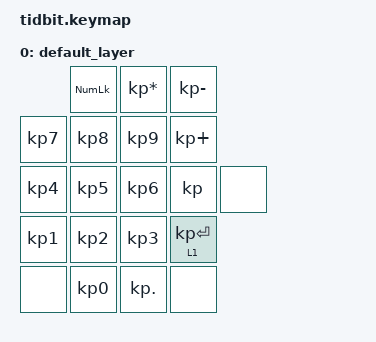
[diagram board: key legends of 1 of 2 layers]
/*
 * Copyright (c) 2020 The ZMK Contributors
 *
 * SPDX-License-Identifier: MIT
 */

#include <behaviors.dtsi>
#include <dt-bindings/zmk/bt.h>
#include <dt-bindings/zmk/outputs.h>
#include <dt-bindings/zmk/keys.h>
#include <dt-bindings/zmk/rgb.h>
#include <dt-bindings/led/led.h>

&encoder_1 {
	status = "okay";
};

/ {
	sensors {
		compatible = "zmk,keymap-sensors";
		sensors = <&encoder_1>;
	};

	keymap {
		compatible = "zmk,keymap";
		
		default_layer {
			bindings = <
								&kp KP_NUMLOCK  &kp KP_ASTERISK &kp KP_MINUS
				&kp KP_NUMBER_7 &kp KP_NUMBER_8 &kp KP_NUMBER_9 &kp KP_PLUS
				&kp KP_NUMBER_4 &kp KP_NUMBER_5 &kp KP_NUMBER_6 &kp &none
				&kp KP_NUMBER_1 &kp KP_NUMBER_2 &kp KP_NUMBER_3 &lt 1 KP_ENTER
				&none           &kp KP_NUMBER_0 &kp KP_DOT      &none
			>;

			sensor-bindings = <&inc_dec_kp C_VOLUME_UP C_VOLUME_DOWN>;
		};

		 func_layer {
			 bindings = <
								&none           &reset          &bootloader
				&out OUT_TOG    &out OUT_USB    &out OUT_BLE    &none
				&bt BT_SEL 0    &bt BT_PRV      &bt BT_NXT      &bt BT_CLR
				&bt BT_SEL 1    &bt BT_SEL 2    &bt BT_SEL 3    &tog 0
				&kp C_MUTE      &none           &none           &none
			 >;

			 sensor-bindings = <&inc_dec_kp C_VOLUME_UP C_VOLUME_DOWN>;
		 };
	};
};

&spi1 {
	compatible = "nordic,nrf-spim";
	status = "okay";
	mosi-pin = <9>;
	// Unused pins, needed for SPI definition, but not used by the ws2812 driver itself.
	sck-pin = <5>;
	miso-pin = <7>;

	led_strip: ws2812@0 {
		compatible = "worldsemi,ws2812-spi";
		label = "WS2812";

		/* SPI */
		reg = <0>; /* ignored, but necessary for SPI bindings */
		spi-max-frequency = <4000000>;

		/* WS2812 */
		chain-length = <8>; /* number of LEDs */
		spi-one-frame = <0x70>;
		spi-zero-frame = <0x40>;
		color-mapping = <LED_COLOR_ID_GREEN LED_COLOR_ID_RED LED_COLOR_ID_BLUE>;
	};
};

/ {
	chosen {
		zmk,underglow = &led_strip;
	};
};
